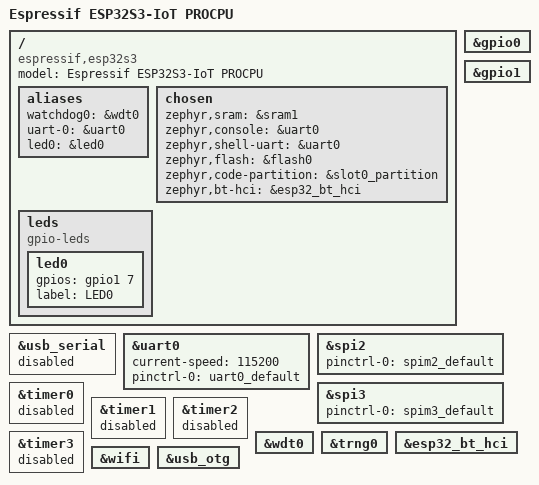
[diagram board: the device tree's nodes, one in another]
/*
 * Copyright (c) 2024-2025 Espressif Systems (Shanghai) Co., Ltd.
 *
 * SPDX-License-Identifier: Apache-2.0
 */
/dts-v1/;

#include <espressif/esp32s3/esp32s3_wroom_n8.dtsi>
#include <zephyr/dt-bindings/input/input-event-codes.h>
#include <zephyr/dt-bindings/input/esp32-touch-sensor-input.h>
#include <espressif/partitions_0x0_amp.dtsi>
#include "esp32s3_iot-pinctrl.dtsi"

/ {
	model = "Espressif ESP32S3-IoT PROCPU";
	compatible = "espressif,esp32s3";

	aliases {
		watchdog0 = &wdt0;
	};

	chosen {
		zephyr,sram = &sram1;
		zephyr,console = &uart0;
		zephyr,shell-uart = &uart0;
		zephyr,flash = &flash0;
		zephyr,code-partition = &slot0_partition;
		zephyr,bt-hci = &esp32_bt_hci;
	};

	aliases {
		uart-0 = &uart0;
        led0 = &led0;
	};

    leds {
		compatible = "gpio-leds";
		led0: led0 {
			gpios = <&gpio1 7 GPIO_ACTIVE_HIGH>;
			label = "LED0";
		};
	};


};

&gpio0 {
	status = "okay";
};

&gpio1 {
	status = "okay";
};

&usb_serial {
	status = "disabled";
};

&uart0 {
	status = "okay";
	current-speed = <115200>;
	pinctrl-0 = <&uart0_default>;
	pinctrl-names = "default";
};

&spi2 {
	#address-cells = <1>;
	#size-cells = <0>;
	status = "okay";
	pinctrl-0 = <&spim2_default>;
	pinctrl-names = "default";
};

&spi3 {
	#address-cells = <1>;
	#size-cells = <0>;
	status = "okay";
	pinctrl-0 = <&spim3_default>;
	pinctrl-names = "default";
};

&timer0 {
	status = "disabled";
};

&timer1 {
	status = "disabled";
};

&timer2 {
	status = "disabled";
};

&timer3 {
	status = "disabled";
};

&wdt0 {
	status = "okay";
};

&trng0 {
	status = "okay";
};

&esp32_bt_hci {
	status = "okay";
};

&wifi {
	status = "okay";
};

zephyr_udc0: &usb_otg {
	status = "okay";
};
